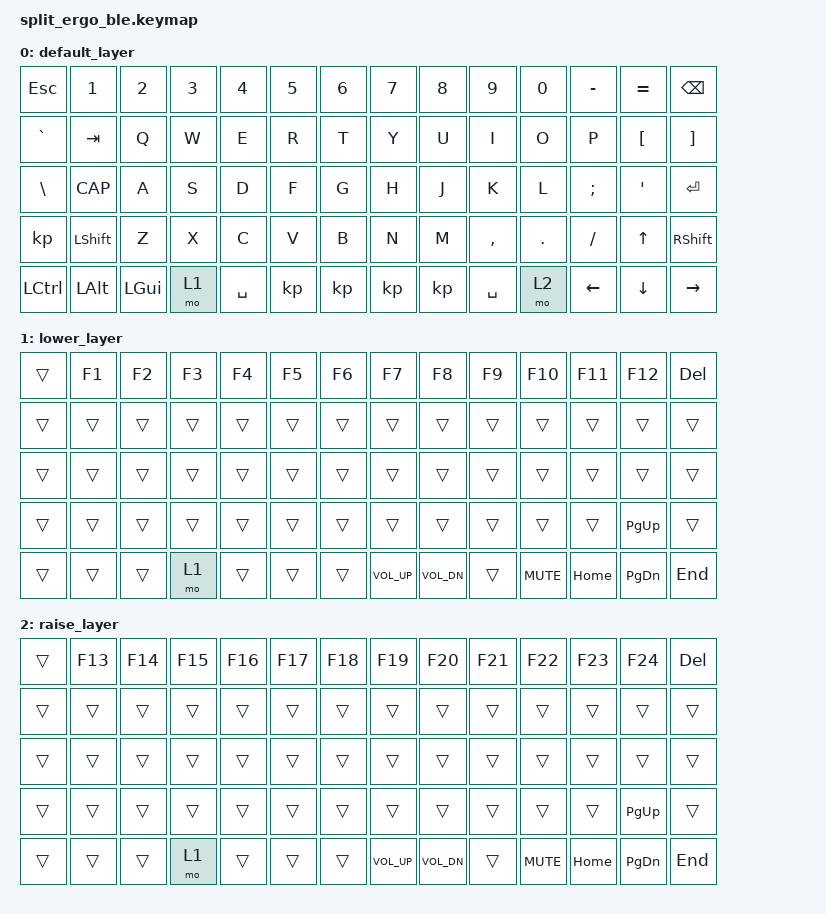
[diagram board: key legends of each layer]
// This file was generated from a template. Edit it to match your keyboard.
// See https://zmk.dev/docs/development/hardware-integration/new-shield for more instructions.

#include <behaviors.dtsi>
#include <dt-bindings/zmk/keys.h>

/ {
    // Define a default keymap here.
    // See https://zmk.dev/docs/development/hardware-integration/new-shield#default-keymap.
    keymap {
        compatible = "zmk,keymap";

        default_layer {
            display_name = "Default Layer";
            
             // --------------------------------------------------------|  |-------------------------------------------------------|
             // |  ESC  |   1   |   2   |   3   |   4   |   5   |   6   |  |   7   |   8   |   9   |   0   |   -   |   =   |  BSPC |
             // |   `   |  TAB  |   q   |   w   |   e   |   r   |   t   |  |   y   |   u   |   i   |   o   |   p   |   [   |   ]   |
             // |   \   |  CAP  |   a   |   s   |   d   |   f   |   g   |  |   h   |   j   |   k   |   l   |   ;   |   '   |  ENT  |
             // |       |  SHFT |   z   |   x   |   c   |   v   |   b   |  |   n   |   m   |   ,   |   .   |   /   |   UP  |  SHFT |
             // |  CTRL |  ALT  |  GUI  |  LWR  |  SPC  |       |       |  |       |       |  SPC  |  RSE  |  LFT  |  DWN  |  RGT  |
             // |--------------------------------------------------------|  |------------------------------------------------------|
            bindings = <
                &kp ESC     &kp N1    &kp N2    &kp N3    &kp N4    &kp N5   &kp N6     &kp N7       &kp N8       &kp N9    &kp N0   &kp MINUS   &kp EQUAL   &kp BSPC
                &kp GRAVE   &kp TAB   &kp Q     &kp W     &kp E     &kp R    &kp T      &kp Y        &kp U        &kp I     &kp O    &kp P       &kp LBKT    &kp RBKT
                &kp BSLH    &kp CAP   &kp A     &kp S     &kp D     &kp F    &kp G      &kp H        &kp J        &kp K     &kp L    &kp SEMI    &kp SQT     &kp RET
                &kp         &kp LSHFT &kp Z     &kp X     &kp C     &kp V    &kp B      &kp N        &kp M        &kp COMMA &kp DOT  &kp FSLH    &kp UP      &kp RSHFT
                &kp LCTRL   &kp LALT  &kp LGUI  &mo 1     &kp SPACE &kp      &kp        &kp          &kp          &kp SPACE &mo 2    &kp LEFT    &kp DOWN    &kp RIGHT
            >;
        };

        lower_layer {
            display_name = "Lower Layer";
            
             // --------------------------------------------------------|  |-------------------------------------------------------|
             // |       |   F1  |   F2  |   F3  |   F4  |   F5  |   F6  |  |   F7  |   F8  |   F9  |  F10  |   F11 |  F12  |  DEL  | 
             // |       |       |       |       |       |       |       |  |       |       |       |       |       |       |       |
             // |       |       |       |       |       |       |       |  |       |       |       |       |       |       |       |
             // |       |       |       |       |       |       |       |  |       |       |       |       |       |  PGUP |       |
             // |       |       |       |  LWR  |       |       |       |  |  VLUP |  VLDN |       |  VLMT |  HOME |  PGDN |  END  |
             // |--------------------------------------------------------|  |------------------------------------------------------|
            bindings = <
                &trans   &kp F1    &kp F2    &kp F3    &kp F4    &kp F5   &kp F6      &kp F7       &kp F8       &kp F9    &kp F10    &kp F11     &kp F12     &kp DEL
                &trans   &trans    &trans    &trans    &trans    &trans   &trans      &trans       &trans       &trans    &trans     &trans      &trans      &trans
                &trans   &trans    &trans    &trans    &trans    &trans   &trans      &trans       &trans       &trans    &trans     &trans      &trans      &trans
                &trans   &trans    &trans    &trans    &trans    &trans   &trans      &trans       &trans       &trans    &trans     &trans      &kp PG_UP   &trans
                &trans   &trans    &trans    &mo 1     &trans    &trans   &trans      &kp C_VOL_UP &kp C_VOL_DN &trans    &kp C_MUTE &kp HOME    &kp PG_DN   &kp END
            >;
        };

        raise_layer {
            display_name = "Raise Layer";
            
             // --------------------------------------------------------|  |-------------------------------------------------------|
             // |       |  F13  |  F14  |  F15  |  F16  |  F17  |  F18  |  |  F19  |  F20  |  F21  |  F22  |  F23  |  F24  |  DEL  | 
             // |       |       |       |       |       |       |       |  |       |       |       |       |       |       |       |
             // |       |       |       |       |       |       |       |  |       |       |       |       |       |       |       |
             // |       |       |       |       |       |       |       |  |       |       |       |       |       |  PGUP |       |
             // |       |       |       |  LWR  |       |       |       |  |  VLUP |  VLDN |       |  VLMT |  HOME |  PGDN |  END  |
             // |--------------------------------------------------------|  |------------------------------------------------------|
            bindings = <
                &trans   &kp F13   &kp F14   &kp F15   &kp F16   &kp F17  &kp F18     &kp F19      &kp F20      &kp F21   &kp F22    &kp F23     &kp F24     &kp DEL
                &trans   &trans    &trans    &trans    &trans    &trans   &trans      &trans       &trans       &trans    &trans     &trans      &trans      &trans
                &trans   &trans    &trans    &trans    &trans    &trans   &trans      &trans       &trans       &trans    &trans     &trans      &trans      &trans
                &trans   &trans    &trans    &trans    &trans    &trans   &trans      &trans       &trans       &trans    &trans     &trans      &kp PG_UP   &trans
                &trans   &trans    &trans    &mo 1     &trans    &trans   &trans      &kp C_VOL_UP &kp C_VOL_DN &trans    &kp C_MUTE &kp HOME    &kp PG_DN   &kp END
            >;
        };
    };
};
